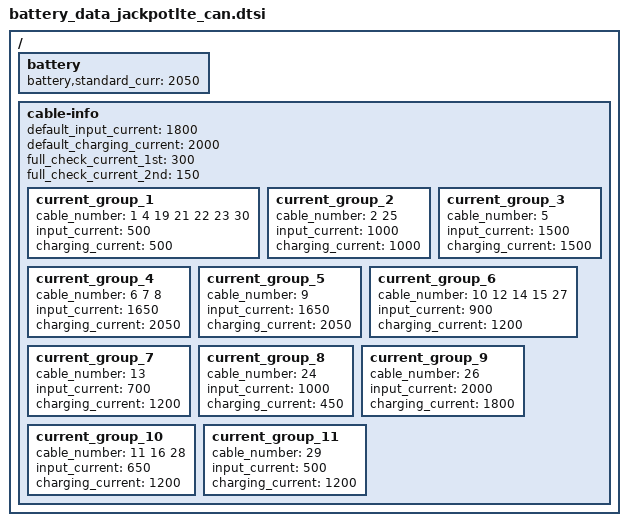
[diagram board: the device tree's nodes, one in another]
/*
 * Jackpot Battery parameters device tree file for board IDs 04 and higher
 *
 * Copyright (C) 2017 Samsung Electronics, Inc.
 *
 * This program is free software; you can redistribute it and/or
 * modify it under the terms of the GNU General Public License
 * as published by the Free Software Foundation; either version 2
 * of the License, or (at your option) any later version.
 *
 * This program is distributed in the hope that it will be useful,
 * but WITHOUT ANY WARRANTY; without even the implied warranty of
 * MERCHANTABILITY or FITNESS FOR A PARTICULAR PURPOSE.  See the
 * GNU General Public License for more details.
 *
 * You should have received a copy of the GNU General Public License
 * along with this program. If not, see <http://www.gnu.org/licenses/>.
 *
 */

/ {
	battery {
	
			battery,standard_curr = <2050>;
	};
	
	cable-info {
		   default_input_current = <1800>;
		   default_charging_current = <2000>;
		   full_check_current_1st = <300>;
		   full_check_current_2nd = <150>;

		   current_group_1 {
		   	       cable_number = <1 4 19 21 22 23 30>;
			       input_current = <500>;
			       charging_current = <500>;
		   };
		   current_group_2 {
		   	       cable_number = <2 25>;
			       input_current = <1000>;
			       charging_current = <1000>;
		  };
		   current_group_3 {
		   	       cable_number = <5>;
			       input_current = <1500>;
			       charging_current = <1500>;
		  };
		   current_group_4 {
		   	       cable_number = <6 7 8>;
			       input_current = <1650>;
			       charging_current = <2050>;
		  };
		   current_group_5 {
		   	       cable_number = <9>;
			       input_current = <1650>;
			       charging_current = <2050>;
		  };
		   current_group_6 {
		   	       cable_number = <10 12 14 15 27>;
			       input_current = <900>;
			       charging_current = <1200>;
		  };
		   current_group_7 {
		   	       cable_number = <13>;
			       input_current = <700>;
			       charging_current = <1200>;
		  };
		   current_group_8 {
		   	       cable_number = <24>;
			       input_current = <1000>;
			       charging_current = <450>;
		  };
		   current_group_9 {
		   	       cable_number = <26>;
			       input_current = <2000>;
			       charging_current = <1800>;
		  };
		   current_group_10 {
		   	       cable_number = <11 16 28>;
			       input_current = <650>;
			       charging_current = <1200>;
		  };
		   current_group_11 {
		   	       cable_number = <29>;
			       input_current = <500>;
			       charging_current = <1200>;
		  };
	};
};
